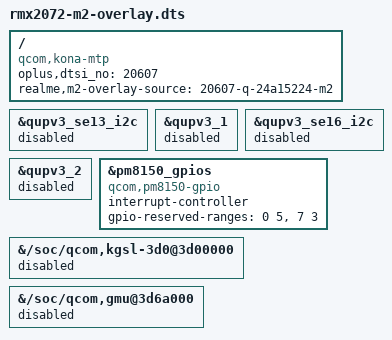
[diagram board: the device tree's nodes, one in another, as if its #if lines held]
// SPDX-License-Identifier: GPL-2.0-only
// Keep the complete source board overlay; no empty/no-op DTBO is used.
#include "kona-mtp-overlay.dts"

/ {
    /delete-property/ oppo,dtsi_no;
    oplus,dtsi_no = <20607>;
    fragment@m2-source {
        target-path = "/";
        __overlay__ {
            // Root DTBO selectors are not payload in a standard FDT overlay.
            // Preserve the board identity used by SCM recovery/PON guards even
            // when the bootloader does not copy selector properties itself.
#ifdef RMX2072_M3_DISPLAY
            // ACK 6.18's UBWC database matches the upstream SoC compatible.
            // Keep all measured board identities for SCM/PON matching.
            compatible = "qcom,kona-mtp", "qcom,kona", "qcom,mtp", "qcom,sm8250";
#else
            compatible = "qcom,kona-mtp", "qcom,kona", "qcom,mtp";
#endif
            oplus,dtsi_no = <20607>;
            realme,m2-overlay-source = "20607-q-24a15224-m2";
        };
    };
#ifdef RMX2072_M3_DISPLAY
    // MSM also matches the legacy KGSL compatible. The downstream node lacks
    // the upstream qcom,gmu link and causes a6xx_gpu_init's BUG_ON(!node).
    // The initial ANGLE/SwiftShader path requires physical DPU scanout only.
    fragment@m3-disable-legacy-gpu {
        target-path = "/soc/qcom,kgsl-3d0@3d00000";
        __overlay__ { status = "disabled"; };
    };
    fragment@m3-disable-legacy-gmu {
        target-path = "/soc/qcom,gmu@3d6a000";
        __overlay__ { status = "disabled"; };
    };
#endif
};

#ifdef RMX2072_M3_INPUT
// The OEM board overlay enables the old SE13 node. A parked compatible alone
// still creates a94000.i2c, preventing the native wrapper's child of that name
// from being registered. Apply the disabled state in this final board overlay.
&qupv3_se13_i2c { status = "disabled"; };
&qupv3_1 { status = "disabled"; };
#ifdef RMX2072_M3_BATTERY
&qupv3_se16_i2c { status = "disabled"; };
&qupv3_2 { status = "disabled"; };
#endif

// The legacy provider never matched the native driver, leaving gpio-keys
// deferred. Preserve its board pin groups and admit only the two volume pads.
&pm8150_gpios {
    compatible = "qcom,pm8150-gpio";
    /delete-property/ interrupts;
    /delete-property/ interrupt-names;
    /delete-property/ qcom,gpios-disallowed;
    interrupt-controller;
    #interrupt-cells = <2>;
    gpio-reserved-ranges = <0 5>, <7 3>;
};

#endif
